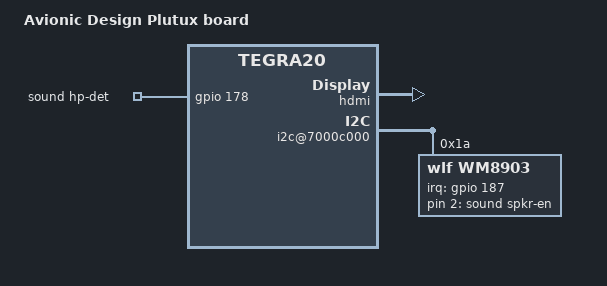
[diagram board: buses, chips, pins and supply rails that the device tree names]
/dts-v1/;

/include/ "tegra20-tamonten.dtsi"

/ {
	model = "Avionic Design Plutux board";
	compatible = "ad,plutux", "ad,tamonten", "nvidia,tegra20";

	host1x {
		hdmi {
			status = "okay";
		};
	};

	i2c@7000c000 {
		wm8903: wm8903@1a {
			compatible = "wlf,wm8903";
			reg = <0x1a>;
			interrupt-parent = <&gpio>;
			interrupts = <187 0x04>;

			gpio-controller;
			#gpio-cells = <2>;

			micdet-cfg = <0>;
			micdet-delay = <100>;
			gpio-cfg = <0xffffffff
				    0xffffffff
				    0
				    0xffffffff
				    0xffffffff>;
		};
	};

	sound {
		compatible = "ad,tegra-audio-plutux",
			     "nvidia,tegra-audio-wm8903";
		nvidia,model = "Avionic Design Plutux";

		nvidia,audio-routing =
			"Headphone Jack", "HPOUTR",
			"Headphone Jack", "HPOUTL",
			"Int Spk", "ROP",
			"Int Spk", "RON",
			"Int Spk", "LOP",
			"Int Spk", "LON",
			"Mic Jack", "MICBIAS",
			"IN1L", "Mic Jack";

		nvidia,i2s-controller = <&tegra_i2s1>;
		nvidia,audio-codec = <&wm8903>;

		nvidia,spkr-en-gpios = <&wm8903 2 0>;
		nvidia,hp-det-gpios = <&gpio 178 0>; /* gpio PW2 */
	};
};
